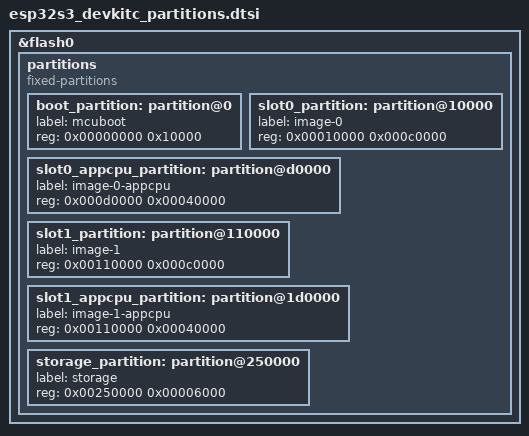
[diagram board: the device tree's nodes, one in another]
/*
 * Copyright (c) 2024 Espressif Systems (Shanghai) Co., Ltd.
 *
 * SPDX-License-Identifier: Apache-2.0
 */

&flash0 {
	partitions {
		compatible = "fixed-partitions";
		#address-cells = <1>;
		#size-cells = <1>;

		boot_partition: partition@0 {
			label = "mcuboot";
			reg = <0x00000000 0x10000>;
		};

		slot0_partition: partition@10000 {
		        label = "image-0";
			reg = <0x00010000 0x000c0000>;
		};

		slot0_appcpu_partition: partition@d0000 {
		        label = "image-0-appcpu";
			reg = <0x000d0000 0x00040000>;
		};

		slot1_partition: partition@110000 {
		        label = "image-1";
			reg = <0x00110000 0x000c0000>;
		};

		slot1_appcpu_partition: partition@1d0000 {
		        label = "image-1-appcpu";
			reg = <0x00110000 0x00040000>;
		};

		storage_partition: partition@250000 {
		        label = "storage";
		        reg = <0x00250000 0x00006000>;
		};
        };
};
